# STM32U575 register map
File version: 1.4
CPU: CM33 r0p1, little endian, MPU, FPU, 4 interrupt priority bits
Registers are 32-bit, read-write, reset 0x0 unless marked. A register's access mark holds for its fields unless they carry their own. Offsets are from the block's base; [hi:lo] are bit positions; lines under a group give offsets from that group; {n}, {i} and the like mark numbered series; 'fields as' and 'values as' point back to an identical list.

## COMP — Comparator
Base 0x46005400
Same registers: SEC_COMP 0x56005400
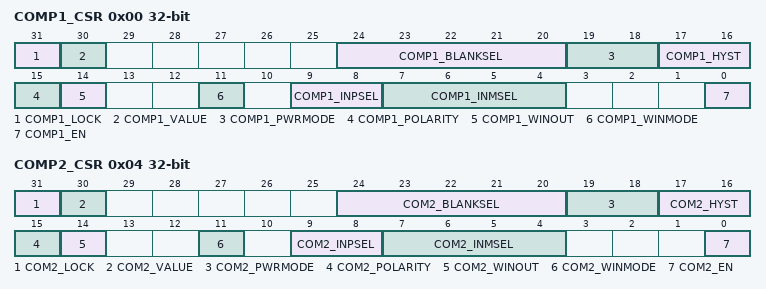
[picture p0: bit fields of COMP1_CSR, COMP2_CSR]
0x00 COMP1_CSR access per field — Comparator 1 control and status register
  [31] COMP1_LOCK rw — COMP1_CSR register lock bit
  [30] COMP1_VALUE ro — Comparator 1 output status bit
  [24:20] COMP1_BLANKSEL rw
  [19:18] COMP1_PWRMODE rw
  [17:16] COMP1_HYST rw — Comparator 1 hysteresis selection bits
  [15] COMP1_POLARITY rw — Comparator 1 polarity selection bit
  [14] COMP1_WINOUT rw
  [11] COMP1_WINMODE rw
  [9:8] COMP1_INPSEL rw — Comparator1 input plus selection bit
  [7:4] COMP1_INMSEL rw — Comparator 1 Input Minus connection configuration bit
  [0] COMP1_EN rw — Comparator 1 enable bit
0x04 COMP2_CSR access per field — Comparator 2 control and status register
  [31] COM2_LOCK rw — COMP2_CSR register lock bit
  [30] COM2_VALUE ro — Comparator 2 output status bit
  [24:20] COM2_BLANKSEL rw
  [19:18] COM2_PWRMODE rw
  [17:16] COM2_HYST rw — Comparator 2 hysteresis selection bits
  [15] COM2_POLARITY rw — Comparator 2 polarity selection bit
  [14] COM2_WINOUT rw
  [11] COM2_WINMODE rw
  [9:8] COM2_INPSEL rw — Comparator 2 input plus selection bit
  [7:4] COM2_INMSEL rw — Comparator 2 Input Minus connection configuration bit
  [0] COM2_EN rw — Comparator 2 enable bit

## VREFBUF — Voltage reference buffer
Base 0x46007400
Same registers: SEC_VREFBUF 0x56007400
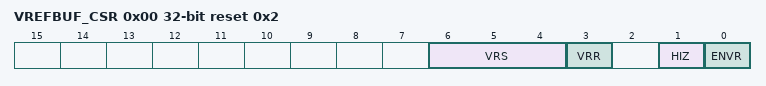
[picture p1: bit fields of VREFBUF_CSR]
0x00 VREFBUF_CSR access per field reset 0x2 — VREFBUF control and status register
  [6:4] VRS rw, [3] VRR ro, [1] HIZ rw, [0] ENVR rw
0x04 VREFBUF_CCR — VREFBUF calibration control register
  [5:0] TRIM

## TSC — Touch sensing controller
Base 0x40024000
Same registers: SEC_TSC 0x50024000
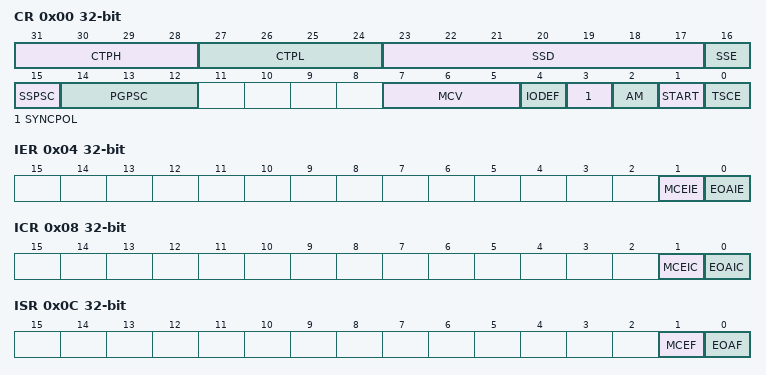
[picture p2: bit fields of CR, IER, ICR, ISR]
0x00 CR — control register
  [31:28] CTPH — Charge transfer pulse high
  [27:24] CTPL — Charge transfer pulse low
  [23:17] SSD — Spread spectrum deviation
  [16] SSE — Spread spectrum enable
  [15] SSPSC — Spread spectrum prescaler
  [14:12] PGPSC — pulse generator prescaler
  [7:5] MCV — Max count value
  [4] IODEF — I/O Default mode
  [3] SYNCPOL — Synchronization pin polarity
  [2] AM — Acquisition mode
  [1] START — Start a new acquisition
  [0] TSCE — Touch sensing controller enable
0x04 IER — interrupt enable register
  [1] MCEIE — Max count error interrupt enable
  [0] EOAIE — End of acquisition interrupt enable
0x08 ICR — interrupt clear register
  [1] MCEIC — Max count error interrupt clear
  [0] EOAIC — End of acquisition interrupt clear
0x0C ISR ro — interrupt status register
  [1] MCEF — Max count error flag
  [0] EOAF — End of acquisition flag
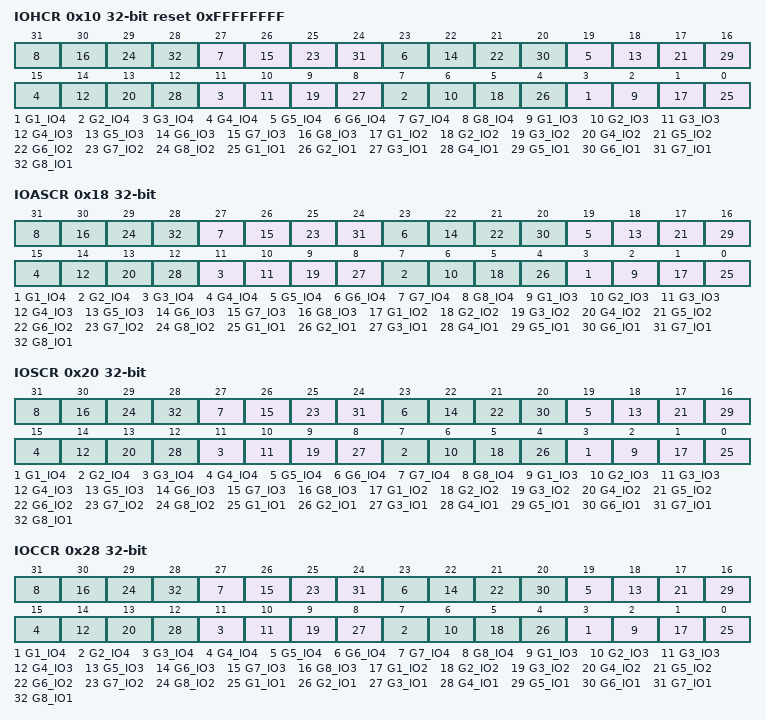
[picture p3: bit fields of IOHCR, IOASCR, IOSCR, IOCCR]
0x10 IOHCR reset 0xFFFFFFFF — I/O hysteresis control register
  [4n-1] G{n}_IO4 (n=1..8), [4n-2] G{n}_IO3 (n=1..8), [4n-3] G{n}_IO2 (n=1..8), [4n-4] G{n}_IO1 (n=1..8)
0x18 IOASCR — I/O analog switch control register
  fields as IOHCR
0x20 IOSCR — I/O sampling control register
  fields as IOHCR
0x28 IOCCR — I/O channel control register
  fields as IOHCR
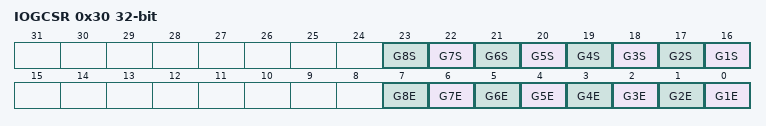
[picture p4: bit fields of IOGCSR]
0x30 IOGCSR access per field — I/O group control status register
  [n+15] G{n}S ro (n=1..8) — Analog I/O group x status
  [n-1] G{n}E rw (n=1..8) — Analog I/O group x enable
{0x30+4i} IOG{i}CR ro (i=1..8) — I/O group x counter register
  [13:0] CNT — Counter value

## CRC — Cyclic redundancy check calculation unit
Base 0x40023000
Same registers: SEC_CRC 0x50023000
0x00 DR reset 0xFFFFFFFF — Data register
  [31:0] DR — Data register bits
0x04 IDR — Independent data register
  [31:0] IDR — General-purpose 8-bit data register bits
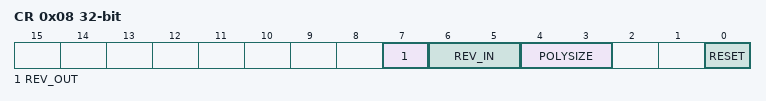
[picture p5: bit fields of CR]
0x08 CR — Control register
  [7] REV_OUT — Reverse output data
  [6:5] REV_IN — Reverse input data
  [4:3] POLYSIZE — Polynomial size
  [0] RESET — RESET bit
0x10 INIT reset 0xFFFFFFFF — Initial CRC value
  [31:0] CRC_INIT — Programmable initial CRC value
0x14 POL reset 0x4C11DB7 — polynomial
  [31:0] POL — Programmable polynomial
